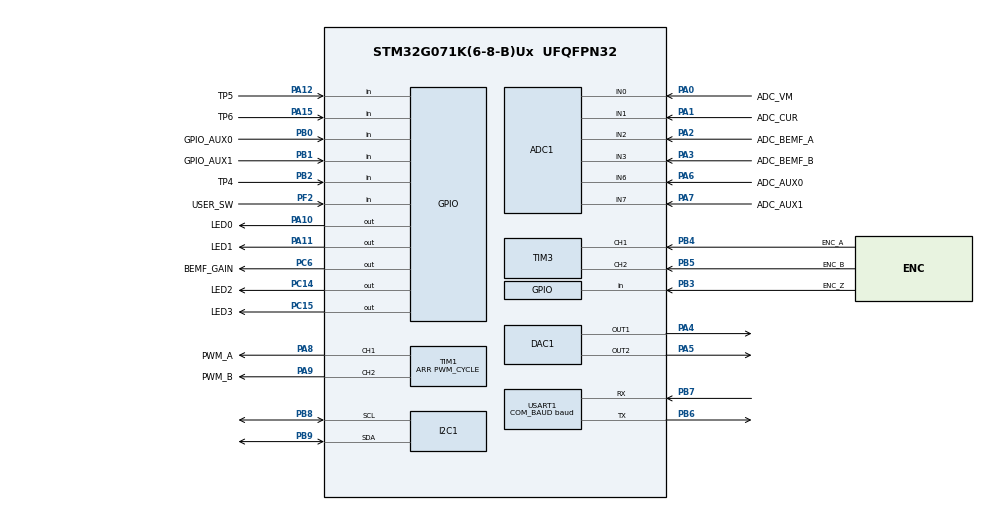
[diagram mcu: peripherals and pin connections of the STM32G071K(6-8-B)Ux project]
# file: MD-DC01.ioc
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ADC1.Channel-0\#ChannelRegularConversion=ADC_CHANNEL_0
ADC1.Channel-1\#ChannelRegularConversion=ADC_CHANNEL_1
ADC1.Channel-2\#ChannelRegularConversion=ADC_CHANNEL_2
ADC1.Channel-3\#ChannelRegularConversion=ADC_CHANNEL_3
ADC1.Channel-4\#ChannelRegularConversion=ADC_CHANNEL_VREFINT
ADC1.Channel-5\#ChannelRegularConversion=ADC_CHANNEL_6
ADC1.Channel-6\#ChannelRegularConversion=ADC_CHANNEL_7
ADC1.ContinuousConvMode=ENABLE
ADC1.DMAContinuousRequests=ENABLE
ADC1.DataAlign=ADC_DATAALIGN_LEFT
ADC1.ExternalTrigConv=ADC_SOFTWARE_START
ADC1.NbrOfConversion=7
ADC1.NbrOfConversionFlag=1
ADC1.Rank-0\#ChannelRegularConversion=1
ADC1.Rank-1\#ChannelRegularConversion=2
ADC1.Rank-2\#ChannelRegularConversion=3
ADC1.Rank-3\#ChannelRegularConversion=4
ADC1.Rank-4\#ChannelRegularConversion=5
ADC1.Rank-5\#ChannelRegularConversion=6
ADC1.Rank-6\#ChannelRegularConversion=7
ADC1.SamplingTime-0\#ChannelRegularConversion=ADC_SAMPLINGTIME_COMMON_1
ADC1.SamplingTime-1\#ChannelRegularConversion=ADC_SAMPLINGTIME_COMMON_1
ADC1.SamplingTime-2\#ChannelRegularConversion=ADC_SAMPLINGTIME_COMMON_1
ADC1.SamplingTime-3\#ChannelRegularConversion=ADC_SAMPLINGTIME_COMMON_1
ADC1.SamplingTime-4\#ChannelRegularConversion=ADC_SAMPLINGTIME_COMMON_2
ADC1.SamplingTime-5\#ChannelRegularConversion=ADC_SAMPLINGTIME_COMMON_2
ADC1.SamplingTime-6\#ChannelRegularConversion=ADC_SAMPLINGTIME_COMMON_2
ADC1.SamplingTimeCommon1=ADC_SAMPLETIME_79CYCLES_5
ADC1.SamplingTimeCommon2=ADC_SAMPLETIME_160CYCLES_5
ADC1.SelectedChannel=ADC_CHANNEL_0|ADC_CHANNEL_1|ADC_CHANNEL_2|ADC_CHANNEL_3|ADC_CHANNEL_6|ADC_CHANNEL_7|ADC_CHANNEL_VREFINT
ADC1.master=1
DAC1.DAC_Channel-DAC_OUT1=DAC_CHANNEL_1
DAC1.DAC_Channel-DAC_OUT2=DAC_CHANNEL_2
Dma.ADC1.0.Direction=DMA_PERIPH_TO_MEMORY
Dma.ADC1.0.EventEnable=DISABLE
Dma.ADC1.0.Instance=DMA1_Channel1
Dma.ADC1.0.MemDataAlignment=DMA_MDATAALIGN_HALFWORD
Dma.ADC1.0.MemInc=DMA_MINC_ENABLE
Dma.ADC1.0.Mode=DMA_CIRCULAR
Dma.ADC1.0.PeriphDataAlignment=DMA_PDATAALIGN_HALFWORD
Dma.ADC1.0.PeriphInc=DMA_PINC_DISABLE
Dma.ADC1.0.Polarity=HAL_DMAMUX_REQ_GEN_RISING
Dma.ADC1.0.Priority=DMA_PRIORITY_VERY_HIGH
Dma.ADC1.0.RequestNumber=1
Dma.ADC1.0.SignalID=NONE
Dma.ADC1.0.SyncEnable=DISABLE
Dma.ADC1.0.SyncPolarity=HAL_DMAMUX_SYNC_NO_EVENT
Dma.ADC1.0.SyncRequestNumber=1
Dma.ADC1.0.SyncSignalID=NONE
Dma.Request0=ADC1
Dma.Request1=USART1_TX
Dma.USART1_TX.1.Direction=DMA_MEMORY_TO_PERIPH
Dma.USART1_TX.1.EventEnable=DISABLE
Dma.USART1_TX.1.Instance=DMA1_Channel2
Dma.USART1_TX.1.MemDataAlignment=DMA_MDATAALIGN_BYTE
Dma.USART1_TX.1.MemInc=DMA_MINC_ENABLE
Dma.USART1_TX.1.Mode=DMA_NORMAL
Dma.USART1_TX.1.PeriphDataAlignment=DMA_PDATAALIGN_BYTE
Dma.USART1_TX.1.PeriphInc=DMA_PINC_DISABLE
Dma.USART1_TX.1.Polarity=HAL_DMAMUX_REQ_GEN_RISING
Dma.USART1_TX.1.Priority=DMA_PRIORITY_HIGH
Dma.USART1_TX.1.RequestNumber=1
Dma.USART1_TX.1.SignalID=NONE
Dma.USART1_TX.1.SyncEnable=DISABLE
Dma.USART1_TX.1.SyncPolarity=HAL_DMAMUX_SYNC_NO_EVENT
Dma.USART1_TX.1.SyncRequestNumber=1
Dma.USART1_TX.1.SyncSignalID=NONE
I2C1.Timing=0x10707DBC
IWDG.Prescaler=IWDG_PRESCALER_32
IWDG.Reload=200
Mcu.Family=STM32G0
Mcu.Name=STM32G071K(6-8-B)Ux
Mcu.Package=UFQFPN32
Mcu.UserConstants=PWM_CYCLE,((PWM_CLOCK / PWM_HZ) - 1);COM_BAUD,(115200);PWM_HZ,(100*1000);PWM_CLOCK,(64*1000*1000)
NVIC.DMA1_Channel1_IRQn=true\:1\:0\:true\:false\:true\:false\:true\:true
NVIC.DMA1_Channel2_3_IRQn=true\:2\:0\:true\:false\:true\:false\:true\:true
NVIC.TIM1_BRK_UP_TRG_COM_IRQn=true\:0\:0\:true\:false\:true\:true\:true\:true
NVIC.USART1_IRQn=true\:0\:0\:false\:false\:true\:true\:true\:true
PA0.GPIO_Label=ADC_VM
PA0.Mode=IN0
PA0.Signal=ADC1_IN0
PA1.GPIO_Label=ADC_CUR
PA1.Mode=IN1
PA1.Signal=ADC1_IN1
PA10.GPIO_Label=LED0
PA10.Signal=GPIO_Output
PA11\ [PA9].GPIO_Label=LED1
PA11\ [PA9].Signal=GPIO_Output
PA12\ [PA10].GPIO_Label=TP5
PA12\ [PA10].Signal=GPIO_Input
PA13.Mode=Serial_Wire
PA13.Signal=SYS_SWDIO
PA14-BOOT0.Mode=Serial_Wire
PA14-BOOT0.Signal=SYS_SWCLK
PA15.GPIO_Label=TP6
PA15.Signal=GPIO_Input
PA2.GPIO_Label=ADC_BEMF_A
PA2.Mode=IN2
PA2.Signal=ADC1_IN2
PA3.GPIO_Label=ADC_BEMF_B
PA3.Mode=IN3
PA3.Signal=ADC1_IN3
PA4.Signal=COMP_DAC11_group
PA5.Signal=COMP_DAC12_group
PA6.GPIO_Label=ADC_AUX0
PA6.Mode=IN6
PA6.Signal=ADC1_IN6
PA7.GPIO_Label=ADC_AUX1
PA7.Mode=IN7
PA7.Signal=ADC1_IN7
PA8.GPIO_Label=PWM_A
PA8.Signal=S_TIM1_CH1
PA9.GPIO_Label=PWM_B
PA9.Signal=S_TIM1_CH2
PB0.GPIO_Label=GPIO_AUX0
PB0.Signal=GPIO_Input
PB1.GPIO_Label=GPIO_AUX1
PB1.Signal=GPIO_Input
PB2.GPIO_Label=TP4
PB2.Signal=GPIO_Input
PB3.GPIO_Label=ENC_Z
PB3.Signal=GPIO_Input
PB4.GPIO_Label=ENC_A
PB4.Signal=S_TIM3_CH1
PB5.GPIO_Label=ENC_B
PB5.Signal=S_TIM3_CH2
PB6.Mode=Asynchronous
PB6.Signal=USART1_TX
PB7.Mode=Asynchronous
PB7.Signal=USART1_RX
PB8.Mode=I2C
PB8.Signal=I2C1_SCL
PB9.Mode=I2C
PB9.Signal=I2C1_SDA
PC14-OSC32_IN\ (PC14).GPIO_Label=LED2
PC14-OSC32_IN\ (PC14).Signal=GPIO_Output
PC15-OSC32_OUT\ (PC15).GPIO_Label=LED3
PC15-OSC32_OUT\ (PC15).Signal=GPIO_Output
PC6.GPIO_Label=BEMF_GAIN
PC6.Signal=GPIO_Output
PF2\ -\ NRST.GPIO_Label=USER_SW
PF2\ -\ NRST.GPIO_PuPd=GPIO_PULLUP
PF2\ -\ NRST.Signal=GPIO_Input
ProjectManager.HeapSize=0x200
ProjectManager.StackSize=0x400
ProjectManager.TargetToolchain=CMake
RCC.ADCFreq_Value=64000000
RCC.AHBFreq_Value=64000000
RCC.CortexFreq_Value=64000000
RCC.EXTERNAL_CLOCK_VALUE=48000
RCC.HCLKFreq_Value=64000000
RCC.HSE_VALUE=8000000
RCC.HSI_VALUE=16000000
RCC.LSE_VALUE=32768
RCC.SYSCLKFreq_VALUE=64000000
RCC.SYSCLKSource=RCC_SYSCLKSOURCE_PLLCLK
RCC.VCOOutputFreq_Value=128000000
SH.COMP_DAC11_group.0=DAC1_OUT1,DAC_OUT1
SH.COMP_DAC12_group.0=DAC1_OUT2,DAC_OUT2
SH.S_TIM1_CH1.0=TIM1_CH1,PWM Generation1 CH1
SH.S_TIM1_CH2.0=TIM1_CH2,PWM Generation2 CH2
SH.S_TIM3_CH1.0=TIM3_CH1,Encoder_Interface
SH.S_TIM3_CH2.0=TIM3_CH2,Encoder_Interface
TIM1.AutoReloadPreload=TIM_AUTORELOAD_PRELOAD_ENABLE
TIM1.Channel-PWM\ Generation1\ CH1=TIM_CHANNEL_1
TIM1.Channel-PWM\ Generation2\ CH2=TIM_CHANNEL_2
TIM1.OCIdleState_1=TIM_OCIDLESTATE_SET
TIM1.OCIdleState_2=TIM_OCIDLESTATE_SET
TIM1.OCPolarity_1=TIM_OCPOLARITY_LOW
TIM1.OCPolarity_2=TIM_OCPOLARITY_LOW
TIM1.Period=PWM_CYCLE
TIM1.TIM_MasterOutputTrigger2=TIM_TRGO2_RESET
TIM3.AutoReloadPreload=TIM_AUTORELOAD_PRELOAD_ENABLE
TIM3.EncoderMode=TIM_ENCODERMODE_TI12
USART1.BaudRate=COM_BAUD
USART1.OverSampling=UART_OVERSAMPLING_8
USART1.OverrunDisableParam=ADVFEATURE_OVERRUN_DISABLE
USART1.VirtualMode-Asynchronous=VM_ASYNC
VP_ADC1_Vref_Input.Mode=IN-Vrefint
VP_IWDG_VS_IWDG.Mode=IWDG_Activate
VP_SYS_VS_DBSignals.Mode=DisableDeadBatterySignals
VP_TIM1_VS_ClockSourceINT.Mode=Internal
board=custom

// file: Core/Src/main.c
/* USER CODE BEGIN Header */
/**
  ******************************************************************************
  * @file           : main.c
  * @brief          : Main program body
  ******************************************************************************
  * @attention
  *
  * Copyright (c) 2023 STMicroelectronics.
  * All rights reserved.
  *
  * This software is licensed under terms that can be found in the LICENSE file
  * in the root directory of this software component.
  * If no LICENSE file comes with this software, it is provided AS-IS.
  *
  ******************************************************************************
  */
/* USER CODE END Header */
#include "main.h"

/* USER CODE BEGIN Includes */
#include "xprintf.h"

#include "led.h"
#include "motor_profiles.h"
#include "usart.h"
#include <stdint.h>
/* USER CODE END Includes */

/* USER CODE BEGIN PTD */
typedef enum
{
  ST_INIT,
  ST_AD_LOW_ZERO,
  ST_AD_HIGH_ZERO,
  ST_RUN
} STATUS;

typedef enum
{
  ADC_GAIN_LOW,
  ADC_GAIN_HIGH
} ADC_GAIN;

typedef enum
{
  ADC1_CH_VM,
  ADC1_CH_CUR,
  ADC1_CH_BEMF_A,
  ADC1_CH_BEMF_B,
  ADC1_CH_VREF,
  ADC1_CH_AUX0,
  ADC1_CH_AUX1,
  ADC1_CH_NUM
} ADC1_CH;

typedef enum
{
  CTRL_VOLT,
  CTRL_VEL,
  CTRL_POS
} CTRL_MODE;

/* USER CODE END PTD */

/* USER CODE BEGIN PD */
#define ADC1_SUM_NUM (1)
#define ADC1_BUF_LEN (ADC1_CH_NUM * ADC1_SUM_NUM)

/* USER CODE END PD */

/* USER CODE BEGIN PV */

// Main process
const static uint32_t ReportIntervalMs = 10;
const static uint32_t AdcZeroDurationMs = 500;
uint32_t ms_ = 0;
static uint32_t report_ms_prev_ = 0;
static uint32_t state_ms_prev_ = 0;
static STATUS state_ = ST_INIT;
static CTRL_MODE mode_ = CTRL_VOLT;

// ADC
const static int32_t AdcExtQ = 4;
const static int32_t AdcLpfQ = 4;
const static int32_t AdcLpfFo = 1;
const static int32_t AdcLpfDnm = 1 << AdcLpfQ;
const static int32_t AdcLpf1_Fo = AdcLpfDnm - AdcLpfFo;
const static int32_t AdcVrefMv = 1212;
const static int32_t BemfDeadBandRaw = 32;

static uint16_t adc1_results_[ADC1_BUF_LEN];
static volatile ADC_GAIN bemf_gain_ = ADC_GAIN_LOW;
static int32_t cur_raw_zero_ = 0;
static int32_t cur_sum_raw_ = 0;
static int32_t cur_sum_num_ = 0;
static bool do_cur_meas_ = false;
static int32_t cur_ma_ = 0;
static int32_t bemf_a_raw_ = 0;
static int32_t bemf_a_high_zero_ = 0;
static int32_t bemf_a_low_zero_ = 0;
static int32_t bemf_b_raw_ = 0;
static int32_t bemf_b_high_zero_ = 0;
static int32_t bemf_b_low_zero_ = 0;
static int32_t bemf_mv_ = 0;
static int32_t vref_raw_ = 0;
static int32_t v_dclink_raw_ = 0;
static int32_t v_dclink_mv_ = 0;
static int32_t adc_aux0_ = 0;
static int32_t adc_aux1_ = 0;
static bool zero_update_ = false;
static bool do_bemf_meas_ = false;

// PWM
const static int32_t BemfMeasureCycle = 250;
const static int32_t BemfMeasureDelay = 10;
const static int32_t BemfMeasureDuration = 50;
const static int32_t BemfDriveDuration = BemfMeasureCycle - BemfMeasureDuration;

static bool enable_output_ = false;
static int32_t bemf_meas_cnt_ = 0;
static int32_t bemf_meas_outoff_ = BemfMeasureCycle - BemfMeasureDuration - 1;
static int32_t bemf_meas_start_ = BemfMeasureCycle - BemfMeasureDuration + BemfMeasureDelay - 1;
static int32_t bemf_meas_end_ = BemfMeasureCycle - 1;
static int32_t oc_ = 0;

// Control
static int32_t target_mv_ = 0;
static int32_t vout_lim_ = 0;
static int32_t v_i_sum_ = 0;
static int32_t vout_mv_ = 0;
const static int32_t ZeroHoldDeadBandMv = 5;
const static int32_t ZeroHoldEnterCycles = 20; // 50 ms at the 2.5 ms control period
static int32_t zero_target_cycles_ = 0;
static bool zero_hold_prev_ = false;

const static int32_t CtrlGainQ = 4;
const static int32_t GainKneeMv = 300;
const static int32_t GainExtra = 10;         // on top of the schedule at very low speed
const static int32_t GainExtraKneeMv = 20;
const static int32_t IntegralGainMinQ4 = 32; // integral stays usable above the knee. Higher feels springy
const static int32_t IntegralClampMv = 200;  // largest error integrated per cycle
const static int32_t BemfSpikeMv = 50;
const static int32_t TargetRampMv = 10;      // per control cycle
static int32_t gain_prev_q4_ = 0;
static int32_t bemf_sum_mv_ = 0;
static int32_t bemf_sum_num_ = 0;
static int32_t target_ref_mv_ = 0;
static int32_t bemf_prev_mv_ = 0;
static bool bemf_held_ = false;
static int32_t gain_multiplier_q4_ = 0;
static int32_t gain_scheduled_q4_ = 0;

static const CtrlConfs * p_mt_conf_ = &MtConfDefault;

// Watchdog
static volatile uint32_t pwm_cb_cnt_ = 0;

// PC command
const static uint32_t PcTargetTimeoutMs = 500;
static bool pc_mode_ = false;
static int32_t pc_target_mv_ = 0;
static uint32_t pc_target_ms_ = 0;

/* USER CODE END PV */

void SystemClock_Config(void);
static void MX_GPIO_Init(void);
static void MX_DMA_Init(void);
static void MX_ADC1_Init(void);
static void MX_DAC1_Init(void);
static void MX_I2C1_Init(void);
static void MX_TIM1_Init(void);
static void MX_TIM3_Init(void);
static void MX_USART1_UART_Init(void);
static void MX_IWDG_Init(void);
/* USER CODE BEGIN PFP */
int absi(const int i);
void adc_init();
void adc_set_gain(const ADC_GAIN g);
void adc_enable_zero_update();
void adc_disable_zero_update();
void adc_enable_bemf_update();
void adc_disable_bemf_update();
void adc_update_bemf();
void adc_latch_cur(const int32_t pwm_oc);
int adc_get_vm();
int adc_get_bemf();
void pwm_init();
void pwm_set_duty(const int32_t rate_q15);
void pwm_enable();
void pwm_disable();
void update_params();
/* USER CODE END PFP */

/* USER CODE BEGIN 0 */
int absi(const int i)
{
  return i < 0 ? -i : i;
}

void adc_init()
{
  LL_DMA_DisableChannel(DMA1, LL_DMA_CHANNEL_1);
  LL_ADC_REG_StopConversion(ADC1);
  LL_ADC_REG_SetDMATransfer(ADC1, LL_ADC_REG_DMA_TRANSFER_NONE);
  LL_ADC_StartCalibration(ADC1);
  while(LL_ADC_IsCalibrationOnGoing(ADC1));
  LL_mDelay(1);
  LL_ADC_REG_ReadConversionData12(ADC1);

  LL_DMA_SetDataLength(DMA1, LL_DMA_CHANNEL_1, ADC1_BUF_LEN);
  LL_DMA_SetPeriphAddress(DMA1, LL_DMA_CHANNEL_1,
                          LL_ADC_DMA_GetRegAddr(ADC1, LL_ADC_DMA_REG_REGULAR_DATA));
  LL_DMA_SetMemoryAddress(DMA1, LL_DMA_CHANNEL_1,
                          (uint32_t)adc1_results_);
  LL_DMA_EnableIT_TC(DMA1, LL_DMA_CHANNEL_1);
  LL_DMA_EnableChannel(DMA1, LL_DMA_CHANNEL_1);

  LL_ADC_REG_SetDMATransfer(ADC1, LL_ADC_REG_DMA_TRANSFER_UNLIMITED);
  LL_ADC_Enable(ADC1);
  LL_ADC_REG_StartConversion(ADC1);
}

void adc_cb()
{
  vref_raw_ = (((int32_t)adc1_results_[ADC1_CH_VREF] << AdcExtQ) * AdcLpfFo
                + vref_raw_ * AdcLpf1_Fo) >> AdcLpfQ;
  v_dclink_raw_ = (((int32_t)adc1_results_[ADC1_CH_VM] << AdcExtQ) * AdcLpfFo
                + v_dclink_raw_ * AdcLpf1_Fo) >> AdcLpfQ;
  const int32_t cur_ext = (int32_t)adc1_results_[ADC1_CH_CUR] << AdcExtQ;
  if (do_cur_meas_)
  {
    cur_sum_raw_ += cur_ext - cur_raw_zero_;
    cur_sum_num_++;
  }
  adc_aux0_ = ((int32_t)adc1_results_[ADC1_CH_AUX0] * AdcLpfFo
                + adc_aux0_ * AdcLpf1_Fo) >> AdcLpfQ;
  adc_aux1_ = ((int32_t)adc1_results_[ADC1_CH_AUX1] * AdcLpfFo
                + adc_aux1_ * AdcLpf1_Fo) >> AdcLpfQ;
  if (zero_update_)
  {
    cur_raw_zero_ = (cur_ext * AdcLpfFo
                    + cur_raw_zero_ * AdcLpf1_Fo) >> AdcLpfQ;
    if (bemf_gain_ == ADC_GAIN_HIGH)
    {
      bemf_a_high_zero_ = (((int32_t)adc1_results_[ADC1_CH_BEMF_A] << AdcExtQ) * AdcLpfFo
                          + bemf_a_high_zero_ * AdcLpf1_Fo) >> AdcLpfQ;
      bemf_b_high_zero_ = (((int32_t)adc1_results_[ADC1_CH_BEMF_B] << AdcExtQ) * AdcLpfFo
                          + bemf_b_high_zero_ * AdcLpf1_Fo) >> AdcLpfQ;
    }
    else
    {
      bemf_a_low_zero_ = (((int32_t)adc1_results_[ADC1_CH_BEMF_A] << AdcExtQ) * AdcLpfFo
                          + bemf_a_low_zero_ * AdcLpf1_Fo) >> AdcLpfQ;
      bemf_b_low_zero_ = (((int32_t)adc1_results_[ADC1_CH_BEMF_B] << AdcExtQ) * AdcLpfFo
                          + bemf_b_low_zero_ * AdcLpf1_Fo) >> AdcLpfQ;
    }
  }
  if (do_bemf_meas_)
    adc_update_bemf();
}

void adc_set_gain(const ADC_GAIN g)
{
  bemf_gain_ = g;
  if (bemf_gain_ == ADC_GAIN_HIGH)
    LL_GPIO_SetOutputPin(BEMF_GAIN_GPIO_Port, BEMF_GAIN_Pin);
  else
    LL_GPIO_ResetOutputPin(BEMF_GAIN_GPIO_Port, BEMF_GAIN_Pin);
}

void adc_enable_zero_update()
{
  zero_update_ = true;
}

void adc_disable_zero_update()
{
  zero_update_ = false;
}

void adc_enable_bemf_update()
{
  do_bemf_meas_ = true;
}

void adc_disable_bemf_update()
{
  do_bemf_meas_ = false;
}

void adc_update_bemf()
{
  int bemf_raw;
  int bemf_mv_raw;
  if (bemf_gain_ == ADC_GAIN_HIGH)
  {
    bemf_a_raw_ = ((int32_t)adc1_results_[ADC1_CH_BEMF_A] << AdcExtQ) - bemf_a_high_zero_;
    bemf_b_raw_ = ((int32_t)adc1_results_[ADC1_CH_BEMF_B] << AdcExtQ) - bemf_b_high_zero_;
    bemf_raw = bemf_a_raw_ > bemf_b_raw_ ? bemf_a_raw_ : -bemf_b_raw_;
    if (bemf_raw > BemfDeadBandRaw) bemf_raw -= BemfDeadBandRaw;
    else if (bemf_raw < -BemfDeadBandRaw) bemf_raw += BemfDeadBandRaw;
    else bemf_raw = 0;
    bemf_mv_raw = (int64_t)bemf_raw * AdcVrefMv * 1249 * 143 / ((int64_t)vref_raw_ * 249 * 1143);
  }
  else
  {
    bemf_a_raw_ = ((int32_t)adc1_results_[ADC1_CH_BEMF_A] << AdcExtQ) - bemf_a_low_zero_;
    bemf_b_raw_ = ((int32_t)adc1_results_[ADC1_CH_BEMF_B] << AdcExtQ) - bemf_b_low_zero_;
    bemf_raw = bemf_a_raw_ > bemf_b_raw_ ? bemf_a_raw_ : -bemf_b_raw_;
    if (bemf_raw > BemfDeadBandRaw) bemf_raw -= BemfDeadBandRaw;
    else if (bemf_raw < -BemfDeadBandRaw) bemf_raw += BemfDeadBandRaw;
    else bemf_raw = 0;
    bemf_mv_raw = (int64_t)bemf_raw * AdcVrefMv * 1249 / (vref_raw_ * 249);
  }
  bemf_sum_mv_ += bemf_mv_raw;
  bemf_sum_num_++;
}

// The shunt only carries current during the on-time, so the drive period mean is divided by the duty.
void adc_latch_cur(const int32_t pwm_oc)
{
  do_cur_meas_ = false;
  int32_t ma = 0;
  if (absi(pwm_oc) >= 6)
  {
    const int32_t mean_raw = cur_sum_raw_ / cur_sum_num_;
    if (mean_raw > 0)
    {
      ma = (int64_t)mean_raw * AdcVrefMv * 50 * PWM_CYCLE / ((int64_t)vref_raw_ * 51 * absi(pwm_oc));
    }
  }
  cur_ma_ = pwm_oc < 0 ? -ma : ma;
}

int adc_get_vm()
{
  return (int64_t)v_dclink_raw_ * AdcVrefMv * 11 / vref_raw_;
}

int adc_get_bemf()
{
  return bemf_mv_;
}

void set_oc()
{
  if (oc_ > 0)
  {
    LL_TIM_OC_SetCompareCH1(PwmTim, 0);
    LL_TIM_OC_SetCompareCH2(PwmTim, oc_);
  }
  else if (oc_ < 0)
  {
    LL_TIM_OC_SetCompareCH1(PwmTim, -oc_);
    LL_TIM_OC_SetCompareCH2(PwmTim, 0);
  }
  else
  {
    LL_TIM_OC_SetCompareCH1(PwmTim, 0);
    LL_TIM_OC_SetCompareCH2(PwmTim, 0);
  }
}

void output_open()
{
  LL_TIM_OC_SetCompareCH1(PwmTim, PWM_CYCLE);
  LL_TIM_OC_SetCompareCH2(PwmTim, PWM_CYCLE);
}

void pwm_init()
{
  pwm_set_duty(0);
  pwm_disable();
  LL_TIM_CC_EnableChannel(PwmTim, LL_TIM_CHANNEL_CH1 | LL_TIM_CHANNEL_CH2);
  LL_TIM_EnableAllOutputs(PwmTim);
  LL_TIM_EnableIT_UPDATE(PwmTim);
  LL_TIM_EnableCounter(PwmTim);
}

/*
rate_q15 : -32768 to 32767
*/
void pwm_set_duty(const int32_t rate_q15)
{
  oc_ = rate_q15 * PWM_CYCLE >> 15;
  if (oc_ >= PWM_CYCLE) oc_ = PWM_CYCLE - 1;
  else if (oc_ <= -PWM_CYCLE) oc_ = -(PWM_CYCLE - 1);
}

void pwm_set_mv(const int32_t mv)
{
  int32_t duty = 0;
  duty = (int64_t)mv * (1<<15) * BemfMeasureCycle / (v_dclink_mv_ * BemfDriveDuration);
  pwm_set_duty(duty);
}

void pwm_enable()
{
  enable_output_ = true;
}

void pwm_disable()
{
  enable_output_ = false;
  output_open();
}

void update_params()
{
  bemf_mv_ = adc_get_bemf();
  v_dclink_mv_ = adc_get_vm();
  // pwm_cb reads vout_lim_, so it must never hold the value before clamping.
  int32_t vout_lim = v_dclink_mv_ * BemfDriveDuration / BemfMeasureCycle;
  if (vout_lim > p_mt_conf_->max_mv) vout_lim = p_mt_conf_->max_mv;
  vout_lim_ = vout_lim;
}

void pwm_cb()
{
  pwm_cb_cnt_++;
  bemf_meas_cnt_++;
  if (bemf_meas_cnt_ == bemf_meas_end_)
  {
    bemf_meas_cnt_ = 0;
    adc_disable_bemf_update();

    if (mode_ != CTRL_VOLT)
    {
      led_on(0);
      // Averaged within this window only, so it adds no delay across control cycles.
      bemf_mv_ = bemf_sum_mv_ / bemf_sum_num_;
      bemf_sum_mv_ = 0;
      bemf_sum_num_ = 0;

      // The rotor cannot jump in one cycle, so a single far off value is a measurement spike.
      // Only needed below the knee: the high gain there would turn it into a large output step.
      if (absi(target_ref_mv_) < GainKneeMv
          && absi(bemf_mv_ - bemf_prev_mv_) > BemfSpikeMv + absi(target_ref_mv_) && !bemf_held_)
      {
        bemf_mv_ = bemf_prev_mv_;
        bemf_held_ = true;
      }
      else
      {
        bemf_held_ = false;
      }
      bemf_prev_mv_ = bemf_mv_;

      if (target_mv_ > target_ref_mv_ + TargetRampMv) target_ref_mv_ += TargetRampMv;
      else if (target_mv_ < target_ref_mv_ - TargetRampMv) target_ref_mv_ -= TargetRampMv;
      else target_ref_mv_ = target_mv_;

      // A target that only touches 0 at very low speed must not reset the integrator.
      if (target_ref_mv_ != 0) zero_target_cycles_ = 0;
      else if (zero_target_cycles_ < ZeroHoldEnterCycles) zero_target_cycles_++;
      const bool zero_hold = (zero_target_cycles_ >= ZeroHoldEnterCycles);
      int32_t err = target_ref_mv_ - bemf_mv_;
      int32_t vout;
      int32_t vout_tmp;

      // The integral built while running would keep driving a slow rotation that BEMF cannot detect.
      if (zero_hold && !zero_hold_prev_) v_i_sum_ = 0;
      zero_hold_prev_ = zero_hold;

      // Inside the band err is 0, so the integrator keeps the torque holding against cogging.
      if (zero_hold)
      {
        if (err > ZeroHoldDeadBandMv) err -= ZeroHoldDeadBandMv;
        else if (err < -ZeroHoldDeadBandMv) err += ZeroHoldDeadBandMv;
        else err = 0;
      }

      // The gain also scales the integral, so rescale it to keep its output across gain changes.
      const int32_t gain_i_q4 = gain_scheduled_q4_ > IntegralGainMinQ4 ? gain_scheduled_q4_ : IntegralGainMinQ4;
      if (gain_prev_q4_ != 0 && gain_i_q4 != gain_prev_q4_)
      {
        v_i_sum_ = (int64_t)v_i_sum_ * gain_prev_q4_ / gain_i_q4;
      }
      gain_prev_q4_ = gain_i_q4;

      // A limit rather than a stop, so a large error from a heavy load still reaches the integral.
      int32_t i_add = err;
      if (i_add > IntegralClampMv) i_add = IntegralClampMv;
      else if (i_add < -IntegralClampMv) i_add = -IntegralClampMv;
      v_i_sum_ += i_add;

      // feedforward
      vout = (target_ref_mv_ * (p_mt_conf_->v_ff_kp_q8)) >> CtrlQ;

      // feedback
      const int32_t fb_p = ((int64_t)err * (p_mt_conf_->v_kp_q8)) >> CtrlQ;
      const int32_t fb_i = ((int64_t)v_i_sum_ * (p_mt_conf_->v_ti_q8)) >> CtrlQ;

      vout += (fb_p * gain_scheduled_q4_) >> CtrlGainQ;
      vout += (fb_i * gain_i_q4) >> CtrlGainQ;

      // compensate brush voltage drop
      // Skipped at zero target: the step at vout = 0 would flip the output by +-brush_co_mv.
      if (!zero_hold)
      {
        if (vout > 0) vout += p_mt_conf_->brush_co_mv;
        else if (vout < 0) vout -= p_mt_conf_->brush_co_mv;
      }

      vout_tmp = vout;

      // limit output
      if (vout > vout_lim_) vout = vout_lim_;
      else if (vout < -vout_lim_) vout = -vout_lim_;

      // cut output while over the current limit
      if (absi(cur_ma_) > p_mt_conf_->max_cur) vout = 0;

      // unti windup
      if ((vout < vout_tmp && err > 0)
          || (vout > vout_tmp && err < 0))
      {
        v_i_sum_ -= i_add;
      }

      vout_mv_ = vout;
      pwm_set_mv(vout);
      led_off(0);
    }
    if (enable_output_)
      set_oc();
    cur_sum_raw_ = 0;
    cur_sum_num_ = 0;
    do_cur_meas_ = true;
  }
  else if (bemf_meas_cnt_ == bemf_meas_outoff_)
  {
    output_open();
    adc_latch_cur(oc_);
  }
  else if (bemf_meas_cnt_ == bemf_meas_start_)
  {
    adc_enable_bemf_update();
  }
}

static bool parse_mv(const char* s, int32_t* mv)
{
  const bool neg = (*s == '-');
  if (neg) ++s;
  if (*s == '\0') return false;
  int32_t val = 0;
  for (; *s != '\0'; ++s)
  {
    if (*s < '0' || *s > '9' || val > 100000) return false;
    val = val * 10 + (*s - '0');
  }
  *mv = neg ? -val : val;
  return true;
}

/*
T<mv> : switch to PC mode and set the target. Must be repeated within PcTargetTimeoutMs.
K     : switch back to the knob.
*/
static void pc_command_poll()
{
  char line[16];
  if (usart_readline(line, sizeof(line)) == 0) return;

  int32_t mv;
  if (line[0] == 'T' && parse_mv(&line[1], &mv))
  {
    if (mv > p_mt_conf_->max_mv) mv = p_mt_conf_->max_mv;
    else if (mv < -p_mt_conf_->max_mv) mv = -p_mt_conf_->max_mv;
    pc_target_mv_ = mv;
    pc_target_ms_ = ms_;
    pc_mode_ = true;
  }
  else if (line[0] == 'K' && line[1] == '\0')
  {
    pc_mode_ = false;
  }
}

/*
Can not use with v1.0 PCB.
*/
int sw_is_pressed()
{
  return LL_GPIO_IsInputPinSet(USER_SW_GPIO_Port, USER_SW_Pin);
}
/* USER CODE END 0 */

int main(void)
{

  /* USER CODE BEGIN 1 */
  char report_buf[256];
  /* USER CODE END 1 */

  /* MCU Configuration--------------------------------------------------------*/

  /* Reset of all peripherals, Initializes the Flash interface and the Systick. */
  LL_APB2_GRP1_EnableClock(LL_APB2_GRP1_PERIPH_SYSCFG);
  LL_APB1_GRP1_EnableClock(LL_APB1_GRP1_PERIPH_PWR);

  /* SysTick_IRQn interrupt configuration */
  NVIC_SetPriority(SysTick_IRQn, 3);

  /** Disable the internal Pull-Up in Dead Battery pins of UCPD peripheral
  */
  LL_SYSCFG_DisableDBATT(LL_SYSCFG_UCPD1_STROBE);

  /* Configure the system clock */
  SystemClock_Config();

  /* USER CODE BEGIN SysInit */
  LL_SYSTICK_EnableIT();
  /* USER CODE END SysInit */

  /* Initialize all configured peripherals */
  MX_GPIO_Init();
  MX_DMA_Init();
  MX_ADC1_Init();
  MX_DAC1_Init();
  MX_I2C1_Init();
  MX_TIM1_Init();
  MX_TIM3_Init();
  MX_USART1_UART_Init();
  MX_IWDG_Init();
  /* USER CODE BEGIN 2 */
  pwm_init();
  adc_init();
  usart_init();
  /* USER CODE END 2 */

  /* Infinite loop */
  /* USER CODE BEGIN WHILE */
  adc_set_gain(ADC_GAIN_LOW);
  gain_multiplier_q4_ = (p_mt_conf_->v_gain_schedule_multiplier) << CtrlGainQ;
  gain_scheduled_q4_ = gain_multiplier_q4_;

  uint32_t pwm_cb_cnt_prev = pwm_cb_cnt_;
  while (1)
  {
    // Refresh only while both the main loop and the control interrupt are running.
    if (pwm_cb_cnt_ != pwm_cb_cnt_prev)
    {
      pwm_cb_cnt_prev = pwm_cb_cnt_;
      LL_IWDG_ReloadCounter(IWDG);
    }
    if (sw_is_pressed())
      pwm_disable();
    update_params();
    /* USER CODE END WHILE */

    /* USER CODE BEGIN 3 */
    switch (state_)
    {
    case ST_INIT:
      pwm_disable();
      adc_set_gain(ADC_GAIN_LOW);
      adc_enable_zero_update();
      state_ = ST_AD_LOW_ZERO;
      state_ms_prev_ = ms_;
      break;

    case ST_AD_LOW_ZERO:
      if (ms_ - state_ms_prev_ >= AdcZeroDurationMs)
      {
        adc_set_gain(ADC_GAIN_HIGH);
        state_ = ST_AD_HIGH_ZERO;
        state_ms_prev_ = ms_;
      }
      break;

    case ST_AD_HIGH_ZERO:
      if (ms_ - state_ms_prev_ >= AdcZeroDurationMs)
      {
        adc_set_gain(ADC_GAIN_LOW);
        pwm_enable();
        adc_disable_zero_update();
        state_ = ST_RUN;
        state_ms_prev_ = ms_;
      }
      break;

    case ST_RUN:
    {
      #if 0
      pwm_set_mv((adc_aux0_ - 32768) * 5000 / 32768);
      #endif

      #if 1
      mode_ = CTRL_VEL;
      int target = (adc_aux0_ - 32768) * (p_mt_conf_->max_mv) / 32768;
      const int db = 30;
      if (target > db) target -= db;
      else if (target < -db) target += db;
      else target = 0;

      pc_command_poll();
      if (pc_mode_)
      {
        // Stays in PC mode on timeout: falling back to the knob could start the motor.
        target = (ms_ - pc_target_ms_ < PcTargetTimeoutMs) ? pc_target_mv_ : 0;
      }

      if (target == 0) led_off(3);
      else led_on(3);

      if (absi(target) < 16000/10) adc_set_gain(ADC_GAIN_HIGH);
      else adc_set_gain(ADC_GAIN_LOW);

      target_mv_ = target;

      // High gain only where cogging dominates. Above the knee it just amplifies the BEMF ripple.
      const int32_t gain_scale = GainKneeMv - absi(target_ref_mv_);
      const int32_t gain_extra_scale = GainExtraKneeMv - absi(target_ref_mv_);
      gain_scheduled_q4_ = (1<<CtrlGainQ) + (gain_scale > 0 ? gain_multiplier_q4_ * gain_scale / GainKneeMv : 0)
                           + (gain_extra_scale > 0 ? (GainExtra << CtrlGainQ) * gain_extra_scale / GainExtraKneeMv : 0);
      #endif
    }
      break;
    }

    if (!usart_is_tx_busy() && ms_ - report_ms_prev_ >= ReportIntervalMs)
    {
      report_ms_prev_ += ReportIntervalMs;

      xsprintf(report_buf, "%7d %1d %5d %5d %6d %5d %6d %8d\n",
                ms_, state_, v_dclink_mv_, cur_ma_, bemf_mv_, target_mv_, vout_mv_, v_i_sum_);
      int len = 0;
      while(report_buf[len++] != '\0');
      usart_tx(report_buf, len);
    }
  }
  /* USER CODE END 3 */
}

void SystemClock_Config(void)
{
  LL_FLASH_SetLatency(LL_FLASH_LATENCY_2);
  while(LL_FLASH_GetLatency() != LL_FLASH_LATENCY_2)
  {
  }

  /* HSI configuration and activation */
  LL_RCC_HSI_Enable();
  while(LL_RCC_HSI_IsReady() != 1)
  {
  }

  /* LSI configuration and activation */
  LL_RCC_LSI_Enable();
  while(LL_RCC_LSI_IsReady() != 1)
  {
  }

  /* Main PLL configuration and activation */
  LL_RCC_PLL_ConfigDomain_SYS(LL_RCC_PLLSOURCE_HSI, LL_RCC_PLLM_DIV_1, 8, LL_RCC_PLLR_DIV_2);
  LL_RCC_PLL_Enable();
  LL_RCC_PLL_EnableDomain_SYS();
  while(LL_RCC_PLL_IsReady() != 1)
  {
  }

  /* Set AHB prescaler*/
  LL_RCC_SetAHBPrescaler(LL_RCC_SYSCLK_DIV_1);

  /* Sysclk activation on the main PLL */
  LL_RCC_SetSysClkSource(LL_RCC_SYS_CLKSOURCE_PLL);
  while(LL_RCC_GetSysClkSource() != LL_RCC_SYS_CLKSOURCE_STATUS_PLL)
  {
  }

  /* Set APB1 prescaler*/
  LL_RCC_SetAPB1Prescaler(LL_RCC_APB1_DIV_1);
  LL_Init1msTick(64000000);
  /* Update CMSIS variable (which can be updated also through SystemCoreClockUpdate function) */
  LL_SetSystemCoreClock(64000000);
}

static void MX_ADC1_Init(void)
{

  LL_ADC_InitTypeDef ADC_InitStruct = {0};
  LL_ADC_REG_InitTypeDef ADC_REG_InitStruct = {0};

  LL_GPIO_InitTypeDef GPIO_InitStruct = {0};

  /* Peripheral clock enable */
  LL_APB2_GRP1_EnableClock(LL_APB2_GRP1_PERIPH_ADC);

  LL_IOP_GRP1_EnableClock(LL_IOP_GRP1_PERIPH_GPIOA);
  /**ADC1 GPIO Configuration
  PA0   ------> ADC1_IN0
  PA1   ------> ADC1_IN1
  PA2   ------> ADC1_IN2
  PA3   ------> ADC1_IN3
  PA6   ------> ADC1_IN6
  PA7   ------> ADC1_IN7
  */
  GPIO_InitStruct.Pin = ADC_VM_Pin;
  GPIO_InitStruct.Mode = LL_GPIO_MODE_ANALOG;
  GPIO_InitStruct.Pull = LL_GPIO_PULL_NO;
  LL_GPIO_Init(ADC_VM_GPIO_Port, &GPIO_InitStruct);

  GPIO_InitStruct.Pin = ADC_CUR_Pin;
  GPIO_InitStruct.Mode = LL_GPIO_MODE_ANALOG;
  GPIO_InitStruct.Pull = LL_GPIO_PULL_NO;
  LL_GPIO_Init(ADC_CUR_GPIO_Port, &GPIO_InitStruct);

  GPIO_InitStruct.Pin = ADC_BEMF_A_Pin;
  GPIO_InitStruct.Mode = LL_GPIO_MODE_ANALOG;
  GPIO_InitStruct.Pull = LL_GPIO_PULL_NO;
  LL_GPIO_Init(ADC_BEMF_A_GPIO_Port, &GPIO_InitStruct);

  GPIO_InitStruct.Pin = ADC_BEMF_B_Pin;
  GPIO_InitStruct.Mode = LL_GPIO_MODE_ANALOG;
  GPIO_InitStruct.Pull = LL_GPIO_PULL_NO;
  LL_GPIO_Init(ADC_BEMF_B_GPIO_Port, &GPIO_InitStruct);

  GPIO_InitStruct.Pin = ADC_AUX0_Pin;
  GPIO_InitStruct.Mode = LL_GPIO_MODE_ANALOG;
  GPIO_InitStruct.Pull = LL_GPIO_PULL_NO;
  LL_GPIO_Init(ADC_AUX0_GPIO_Port, &GPIO_InitStruct);

  GPIO_InitStruct.Pin = ADC_AUX1_Pin;
  GPIO_InitStruct.Mode = LL_GPIO_MODE_ANALOG;
  GPIO_InitStruct.Pull = LL_GPIO_PULL_NO;
  LL_GPIO_Init(ADC_AUX1_GPIO_Port, &GPIO_InitStruct);

  /* ADC1 DMA Init */

  /* ADC1 Init */
  LL_DMA_SetPeriphRequest(DMA1, LL_DMA_CHANNEL_1, LL_DMAMUX_REQ_ADC1);

  LL_DMA_SetDataTransferDirection(DMA1, LL_DMA_CHANNEL_1, LL_DMA_DIRECTION_PERIPH_TO_MEMORY);

  LL_DMA_SetChannelPriorityLevel(DMA1, LL_DMA_CHANNEL_1, LL_DMA_PRIORITY_VERYHIGH);

  LL_DMA_SetMode(DMA1, LL_DMA_CHANNEL_1, LL_DMA_MODE_CIRCULAR);

  LL_DMA_SetPeriphIncMode(DMA1, LL_DMA_CHANNEL_1, LL_DMA_PERIPH_NOINCREMENT);

  LL_DMA_SetMemoryIncMode(DMA1, LL_DMA_CHANNEL_1, LL_DMA_MEMORY_INCREMENT);

  LL_DMA_SetPeriphSize(DMA1, LL_DMA_CHANNEL_1, LL_DMA_PDATAALIGN_HALFWORD);

  LL_DMA_SetMemorySize(DMA1, LL_DMA_CHANNEL_1, LL_DMA_MDATAALIGN_HALFWORD);

  /** Configure the global features of the ADC (Clock, Resolution, Data Alignment and number of conversion)
  */

   #define ADC_CHANNEL_CONF_RDY_TIMEOUT_MS ( 1U)
   #if (USE_TIMEOUT == 1)
   uint32_t Timeout ; /* Variable used for Timeout management */
   #endif /* USE_TIMEOUT */

  ADC_InitStruct.Clock = LL_ADC_CLOCK_SYNC_PCLK_DIV2;
  ADC_InitStruct.Resolution = LL_ADC_RESOLUTION_12B;
  ADC_InitStruct.DataAlignment = LL_ADC_DATA_ALIGN_LEFT;
  ADC_InitStruct.LowPowerMode = LL_ADC_LP_MODE_NONE;
  LL_ADC_Init(ADC1, &ADC_InitStruct);
  LL_ADC_REG_SetSequencerConfigurable(ADC1, LL_ADC_REG_SEQ_CONFIGURABLE);

   /* Poll for ADC channel configuration ready */
   #if (USE_TIMEOUT == 1)
   Timeout = ADC_CHANNEL_CONF_RDY_TIMEOUT_MS;
   #endif /* USE_TIMEOUT */
   while (LL_ADC_IsActiveFlag_CCRDY(ADC1) == 0)
     {
   #if (USE_TIMEOUT == 1)
   /* Check Systick counter flag to decrement the time-out value */
   if (LL_SYSTICK_IsActiveCounterFlag())
     {
   if(Timeout-- == 0)
         {
   Error_Handler();
         }
     }
   #endif /* USE_TIMEOUT */
     }
   /* Clear flag ADC channel configuration ready */
   LL_ADC_ClearFlag_CCRDY(ADC1);
  ADC_REG_InitStruct.TriggerSource = LL_ADC_REG_TRIG_SOFTWARE;
  ADC_REG_InitStruct.SequencerLength = LL_ADC_REG_SEQ_SCAN_ENABLE_7RANKS;
  ADC_REG_InitStruct.ContinuousMode = LL_ADC_REG_CONV_CONTINUOUS;
  ADC_REG_InitStruct.DMATransfer = LL_ADC_REG_DMA_TRANSFER_UNLIMITED;
  ADC_REG_InitStruct.Overrun = LL_ADC_REG_OVR_DATA_PRESERVED;
  LL_ADC_REG_Init(ADC1, &ADC_REG_InitStruct);
  LL_ADC_SetOverSamplingScope(ADC1, LL_ADC_OVS_DISABLE);
  LL_ADC_SetTriggerFrequencyMode(ADC1, LL_ADC_CLOCK_FREQ_MODE_HIGH);
  LL_ADC_SetCommonPathInternalCh(__LL_ADC_COMMON_INSTANCE(ADC1), LL_ADC_PATH_INTERNAL_VREFINT);
  LL_ADC_SetSamplingTimeCommonChannels(ADC1, LL_ADC_SAMPLINGTIME_COMMON_1, LL_ADC_SAMPLINGTIME_79CYCLES_5);
  LL_ADC_SetSamplingTimeCommonChannels(ADC1, LL_ADC_SAMPLINGTIME_COMMON_2, LL_ADC_SAMPLINGTIME_160CYCLES_5);
  LL_ADC_DisableIT_EOC(ADC1);
  LL_ADC_DisableIT_EOS(ADC1);

   /* Enable ADC internal voltage regulator */
   LL_ADC_EnableInternalRegulator(ADC1);
   /* Delay for ADC internal voltage regulator stabilization. */
   /* Compute number of CPU cycles to wait for, from delay in us. */
   /* Note: Variable divided by 2 to compensate partially */
   /* CPU processing cycles (depends on compilation optimization). */
   /* Note: If system core clock frequency is below 200kHz, wait time */
   /* is only a few CPU processing cycles. */
   __IO uint32_t wait_loop_index;
   wait_loop_index = ((LL_ADC_DELAY_INTERNAL_REGUL_STAB_US * (SystemCoreClock / (100000 * 2))) / 10);
   while(wait_loop_index != 0)
     {
   wait_loop_index--;
     }

  /** Configure Regular Channel
  */
  LL_ADC_REG_SetSequencerRanks(ADC1, LL_ADC_REG_RANK_1, LL_ADC_CHANNEL_0);
  LL_ADC_SetChannelSamplingTime(ADC1, LL_ADC_CHANNEL_0, LL_ADC_SAMPLINGTIME_COMMON_1);

  /** Configure Regular Channel
  */
  LL_ADC_REG_SetSequencerRanks(ADC1, LL_ADC_REG_RANK_2, LL_ADC_CHANNEL_1);

   /* Poll for ADC channel configuration ready */
   #if (USE_TIMEOUT == 1)
   Timeout = ADC_CHANNEL_CONF_RDY_TIMEOUT_MS;
   #endif /* USE_TIMEOUT */
   while (LL_ADC_IsActiveFlag_CCRDY(ADC1) == 0)
     {
   #if (USE_TIMEOUT == 1)
   /* Check Systick counter flag to decrement the time-out value */
   if (LL_SYSTICK_IsActiveCounterFlag())
     {
   if(Timeout-- == 0)
         {
   Error_Handler();
         }
     }
   #endif /* USE_TIMEOUT */
     }
   /* Clear flag ADC channel configuration ready */
   LL_ADC_ClearFlag_CCRDY(ADC1);
  LL_ADC_SetChannelSamplingTime(ADC1, LL_ADC_CHANNEL_1, LL_ADC_SAMPLINGTIME_COMMON_1);

  /** Configure Regular Channel
  */
  LL_ADC_REG_SetSequencerRanks(ADC1, LL_ADC_REG_RANK_3, LL_ADC_CHANNEL_2);

   /* Poll for ADC channel configuration ready */
   #if (USE_TIMEOUT == 1)
   Timeout = ADC_CHANNEL_CONF_RDY_TIMEOUT_MS;
   #endif /* USE_TIMEOUT */
   while (LL_ADC_IsActiveFlag_CCRDY(ADC1) == 0)
     {
   #if (USE_TIMEOUT == 1)
   /* Check Systick counter flag to decrement the time-out value */
   if (LL_SYSTICK_IsActiveCounterFlag())
     {
   if(Timeout-- == 0)
         {
   Error_Handler();
         }
     }
   #endif /* USE_TIMEOUT */
     }
   /* Clear flag ADC channel configuration ready */
   LL_ADC_ClearFlag_CCRDY(ADC1);
  LL_ADC_SetChannelSamplingTime(ADC1, LL_ADC_CHANNEL_2, LL_ADC_SAMPLINGTIME_COMMON_1);

  /** Configure Regular Channel
  */
  LL_ADC_REG_SetSequencerRanks(ADC1, LL_ADC_REG_RANK_4, LL_ADC_CHANNEL_3);

   /* Poll for ADC channel configuration ready */
   #if (USE_TIMEOUT == 1)
   Timeout = ADC_CHANNEL_CONF_RDY_TIMEOUT_MS;
   #endif /* USE_TIMEOUT */
   while (LL_ADC_IsActiveFlag_CCRDY(ADC1) == 0)
     {
   #if (USE_TIMEOUT == 1)
   /* Check Systick counter flag to decrement the time-out value */
   if (LL_SYSTICK_IsActiveCounterFlag())
     {
   if(Timeout-- == 0)
         {
   Error_Handler();
         }
     }
   #endif /* USE_TIMEOUT */
     }
   /* Clear flag ADC channel configuration ready */
   LL_ADC_ClearFlag_CCRDY(ADC1);
  LL_ADC_SetChannelSamplingTime(ADC1, LL_ADC_CHANNEL_3, LL_ADC_SAMPLINGTIME_COMMON_1);

  /** Configure Regular Channel
  */
  LL_ADC_REG_SetSequencerRanks(ADC1, LL_ADC_REG_RANK_5, LL_ADC_CHANNEL_VREFINT);

   /* Poll for ADC channel configuration ready */
   #if (USE_TIMEOUT == 1)
   Timeout = ADC_CHANNEL_CONF_RDY_TIMEOUT_MS;
   #endif /* USE_TIMEOUT */
   while (LL_ADC_IsActiveFlag_CCRDY(ADC1) == 0)
     {
   #if (USE_TIMEOUT == 1)
   /* Check Systick counter flag to decrement the time-out value */
   if (LL_SYSTICK_IsActiveCounterFlag())
     {
   if(Timeout-- == 0)
         {
   Error_Handler();
         }
     }
   #endif /* USE_TIMEOUT */
     }
   /* Clear flag ADC channel configuration ready */
   LL_ADC_ClearFlag_CCRDY(ADC1);
  LL_ADC_SetChannelSamplingTime(ADC1, LL_ADC_CHANNEL_VREFINT, LL_ADC_SAMPLINGTIME_COMMON_2);

  /** Configure Regular Channel
  */
  LL_ADC_REG_SetSequencerRanks(ADC1, LL_ADC_REG_RANK_6, LL_ADC_CHANNEL_6);

   /* Poll for ADC channel configuration ready */
   #if (USE_TIMEOUT == 1)
   Timeout = ADC_CHANNEL_CONF_RDY_TIMEOUT_MS;
   #endif /* USE_TIMEOUT */
   while (LL_ADC_IsActiveFlag_CCRDY(ADC1) == 0)
     {
   #if (USE_TIMEOUT == 1)
   /* Check Systick counter flag to decrement the time-out value */
   if (LL_SYSTICK_IsActiveCounterFlag())
     {
   if(Timeout-- == 0)
         {
   Error_Handler();
         }
     }
   #endif /* USE_TIMEOUT */
     }
   /* Clear flag ADC channel configuration ready */
   LL_ADC_ClearFlag_CCRDY(ADC1);
  LL_ADC_SetChannelSamplingTime(ADC1, LL_ADC_CHANNEL_6, LL_ADC_SAMPLINGTIME_COMMON_2);

  /** Configure Regular Channel
  */
  LL_ADC_REG_SetSequencerRanks(ADC1, LL_ADC_REG_RANK_7, LL_ADC_CHANNEL_7);

   /* Poll for ADC channel configuration ready */
   #if (USE_TIMEOUT == 1)
   Timeout = ADC_CHANNEL_CONF_RDY_TIMEOUT_MS;
   #endif /* USE_TIMEOUT */
   while (LL_ADC_IsActiveFlag_CCRDY(ADC1) == 0)
     {
   #if (USE_TIMEOUT == 1)
   /* Check Systick counter flag to decrement the time-out value */
   if (LL_SYSTICK_IsActiveCounterFlag())
     {
   if(Timeout-- == 0)
         {
   Error_Handler();
         }
     }
   #endif /* USE_TIMEOUT */
     }
   /* Clear flag ADC channel configuration ready */
   LL_ADC_ClearFlag_CCRDY(ADC1);
  LL_ADC_SetChannelSamplingTime(ADC1, LL_ADC_CHANNEL_7, LL_ADC_SAMPLINGTIME_COMMON_2);

}

static void MX_DAC1_Init(void)
{

  LL_DAC_InitTypeDef DAC_InitStruct = {0};

  LL_GPIO_InitTypeDef GPIO_InitStruct = {0};

  /* Peripheral clock enable */
  LL_APB1_GRP1_EnableClock(LL_APB1_GRP1_PERIPH_DAC1);

  LL_IOP_GRP1_EnableClock(LL_IOP_GRP1_PERIPH_GPIOA);
  /**DAC1 GPIO Configuration
  PA4   ------> DAC1_OUT1
  PA5   ------> DAC1_OUT2
  */
  GPIO_InitStruct.Pin = LL_GPIO_PIN_4;
  GPIO_InitStruct.Mode = LL_GPIO_MODE_ANALOG;
  GPIO_InitStruct.Pull = LL_GPIO_PULL_NO;
  LL_GPIO_Init(GPIOA, &GPIO_InitStruct);

  GPIO_InitStruct.Pin = LL_GPIO_PIN_5;
  GPIO_InitStruct.Mode = LL_GPIO_MODE_ANALOG;
  GPIO_InitStruct.Pull = LL_GPIO_PULL_NO;
  LL_GPIO_Init(GPIOA, &GPIO_InitStruct);

  /** DAC channel OUT1 config
  */
  DAC_InitStruct.TriggerSource = LL_DAC_TRIG_SOFTWARE;
  DAC_InitStruct.WaveAutoGeneration = LL_DAC_WAVE_AUTO_GENERATION_NONE;
  DAC_InitStruct.OutputBuffer = LL_DAC_OUTPUT_BUFFER_ENABLE;
  DAC_InitStruct.OutputConnection = LL_DAC_OUTPUT_CONNECT_GPIO;
  DAC_InitStruct.OutputMode = LL_DAC_OUTPUT_MODE_NORMAL;
  LL_DAC_Init(DAC1, LL_DAC_CHANNEL_1, &DAC_InitStruct);
  LL_DAC_DisableTrigger(DAC1, LL_DAC_CHANNEL_1);

  /** DAC channel OUT2 config
  */
  LL_DAC_Init(DAC1, LL_DAC_CHANNEL_2, &DAC_InitStruct);
  LL_DAC_DisableTrigger(DAC1, LL_DAC_CHANNEL_2);

}

static void MX_I2C1_Init(void)
{

  LL_I2C_InitTypeDef I2C_InitStruct = {0};

  LL_GPIO_InitTypeDef GPIO_InitStruct = {0};

  LL_RCC_SetI2CClockSource(LL_RCC_I2C1_CLKSOURCE_PCLK1);

  LL_IOP_GRP1_EnableClock(LL_IOP_GRP1_PERIPH_GPIOB);
  /**I2C1 GPIO Configuration
  PB9   ------> I2C1_SDA
  PB8   ------> I2C1_SCL
  */
  GPIO_InitStruct.Pin = LL_GPIO_PIN_9;
  GPIO_InitStruct.Mode = LL_GPIO_MODE_ALTERNATE;
  GPIO_InitStruct.Speed = LL_GPIO_SPEED_FREQ_LOW;
  GPIO_InitStruct.OutputType = LL_GPIO_OUTPUT_OPENDRAIN;
  GPIO_InitStruct.Pull = LL_GPIO_PULL_NO;
  GPIO_InitStruct.Alternate = LL_GPIO_AF_6;
  LL_GPIO_Init(GPIOB, &GPIO_InitStruct);

  GPIO_InitStruct.Pin = LL_GPIO_PIN_8;
  GPIO_InitStruct.Mode = LL_GPIO_MODE_ALTERNATE;
  GPIO_InitStruct.Speed = LL_GPIO_SPEED_FREQ_LOW;
  GPIO_InitStruct.OutputType = LL_GPIO_OUTPUT_OPENDRAIN;
  GPIO_InitStruct.Pull = LL_GPIO_PULL_NO;
  GPIO_InitStruct.Alternate = LL_GPIO_AF_6;
  LL_GPIO_Init(GPIOB, &GPIO_InitStruct);

  /* Peripheral clock enable */
  LL_APB1_GRP1_EnableClock(LL_APB1_GRP1_PERIPH_I2C1);

  /** I2C Initialization
  */
  I2C_InitStruct.PeripheralMode = LL_I2C_MODE_I2C;
  I2C_InitStruct.Timing = 0x10707DBC;
  I2C_InitStruct.AnalogFilter = LL_I2C_ANALOGFILTER_ENABLE;
  I2C_InitStruct.DigitalFilter = 0;
  I2C_InitStruct.OwnAddress1 = 0;
  I2C_InitStruct.TypeAcknowledge = LL_I2C_ACK;
  I2C_InitStruct.OwnAddrSize = LL_I2C_OWNADDRESS1_7BIT;
  LL_I2C_Init(I2C1, &I2C_InitStruct);
  LL_I2C_EnableAutoEndMode(I2C1);
  LL_I2C_SetOwnAddress2(I2C1, 0, LL_I2C_OWNADDRESS2_NOMASK);
  LL_I2C_DisableOwnAddress2(I2C1);
  LL_I2C_DisableGeneralCall(I2C1);
  LL_I2C_EnableClockStretching(I2C1);

}

static void MX_IWDG_Init(void)
{

  LL_IWDG_Enable(IWDG);
  LL_IWDG_EnableWriteAccess(IWDG);
  LL_IWDG_SetPrescaler(IWDG, LL_IWDG_PRESCALER_32);
  LL_IWDG_SetReloadCounter(IWDG, 200);
  while (LL_IWDG_IsReady(IWDG) != 1)
  {
  }

  LL_IWDG_ReloadCounter(IWDG);

}

static void MX_TIM1_Init(void)
{

  LL_TIM_InitTypeDef TIM_InitStruct = {0};
  LL_TIM_OC_InitTypeDef TIM_OC_InitStruct = {0};
  LL_TIM_BDTR_InitTypeDef TIM_BDTRInitStruct = {0};

  LL_GPIO_InitTypeDef GPIO_InitStruct = {0};

  LL_RCC_SetTIMClockSource(LL_RCC_TIM1_CLKSOURCE_PCLK1);

  /* Peripheral clock enable */
  LL_APB2_GRP1_EnableClock(LL_APB2_GRP1_PERIPH_TIM1);

  /* TIM1 interrupt Init */
  NVIC_SetPriority(TIM1_BRK_UP_TRG_COM_IRQn, 0);
  NVIC_EnableIRQ(TIM1_BRK_UP_TRG_COM_IRQn);

  TIM_InitStruct.Prescaler = 0;
  TIM_InitStruct.CounterMode = LL_TIM_COUNTERMODE_UP;
  TIM_InitStruct.Autoreload = PWM_CYCLE;
  TIM_InitStruct.ClockDivision = LL_TIM_CLOCKDIVISION_DIV1;
  TIM_InitStruct.RepetitionCounter = 0;
  LL_TIM_Init(TIM1, &TIM_InitStruct);
  LL_TIM_EnableARRPreload(TIM1);
  LL_TIM_SetClockSource(TIM1, LL_TIM_CLOCKSOURCE_INTERNAL);
  LL_TIM_OC_EnablePreload(TIM1, LL_TIM_CHANNEL_CH1);
  TIM_OC_InitStruct.OCMode = LL_TIM_OCMODE_PWM1;
  TIM_OC_InitStruct.OCState = LL_TIM_OCSTATE_DISABLE;
  TIM_OC_InitStruct.OCNState = LL_TIM_OCSTATE_DISABLE;
  TIM_OC_InitStruct.CompareValue = 0;
  TIM_OC_InitStruct.OCPolarity = LL_TIM_OCPOLARITY_LOW;
  TIM_OC_InitStruct.OCNPolarity = LL_TIM_OCPOLARITY_HIGH;
  TIM_OC_InitStruct.OCIdleState = LL_TIM_OCIDLESTATE_HIGH;
  TIM_OC_InitStruct.OCNIdleState = LL_TIM_OCIDLESTATE_LOW;
  LL_TIM_OC_Init(TIM1, LL_TIM_CHANNEL_CH1, &TIM_OC_InitStruct);
  LL_TIM_OC_DisableFast(TIM1, LL_TIM_CHANNEL_CH1);
  LL_TIM_OC_EnablePreload(TIM1, LL_TIM_CHANNEL_CH2);
  LL_TIM_OC_Init(TIM1, LL_TIM_CHANNEL_CH2, &TIM_OC_InitStruct);
  LL_TIM_OC_DisableFast(TIM1, LL_TIM_CHANNEL_CH2);
  LL_TIM_SetTriggerOutput(TIM1, LL_TIM_TRGO_RESET);
  LL_TIM_SetTriggerOutput2(TIM1, LL_TIM_TRGO2_RESET);
  LL_TIM_DisableMasterSlaveMode(TIM1);
  TIM_BDTRInitStruct.OSSRState = LL_TIM_OSSR_DISABLE;
  TIM_BDTRInitStruct.OSSIState = LL_TIM_OSSI_DISABLE;
  TIM_BDTRInitStruct.LockLevel = LL_TIM_LOCKLEVEL_OFF;
  TIM_BDTRInitStruct.DeadTime = 0;
  TIM_BDTRInitStruct.BreakState = LL_TIM_BREAK_DISABLE;
  TIM_BDTRInitStruct.BreakPolarity = LL_TIM_BREAK_POLARITY_HIGH;
  TIM_BDTRInitStruct.BreakFilter = LL_TIM_BREAK_FILTER_FDIV1;
  TIM_BDTRInitStruct.BreakAFMode = LL_TIM_BREAK_AFMODE_INPUT;
  TIM_BDTRInitStruct.Break2State = LL_TIM_BREAK2_DISABLE;
  TIM_BDTRInitStruct.Break2Polarity = LL_TIM_BREAK2_POLARITY_HIGH;
  TIM_BDTRInitStruct.Break2Filter = LL_TIM_BREAK2_FILTER_FDIV1;
  TIM_BDTRInitStruct.Break2AFMode = LL_TIM_BREAK_AFMODE_INPUT;
  TIM_BDTRInitStruct.AutomaticOutput = LL_TIM_AUTOMATICOUTPUT_DISABLE;
  LL_TIM_BDTR_Init(TIM1, &TIM_BDTRInitStruct);
  LL_IOP_GRP1_EnableClock(LL_IOP_GRP1_PERIPH_GPIOA);
  /**TIM1 GPIO Configuration
  PA8   ------> TIM1_CH1
  PA9   ------> TIM1_CH2
  */
  GPIO_InitStruct.Pin = PWM_A_Pin;
  GPIO_InitStruct.Mode = LL_GPIO_MODE_ALTERNATE;
  GPIO_InitStruct.Speed = LL_GPIO_SPEED_FREQ_LOW;
  GPIO_InitStruct.OutputType = LL_GPIO_OUTPUT_PUSHPULL;
  GPIO_InitStruct.Pull = LL_GPIO_PULL_NO;
  GPIO_InitStruct.Alternate = LL_GPIO_AF_2;
  LL_GPIO_Init(PWM_A_GPIO_Port, &GPIO_InitStruct);

  GPIO_InitStruct.Pin = PWM_B_Pin;
  GPIO_InitStruct.Mode = LL_GPIO_MODE_ALTERNATE;
  GPIO_InitStruct.Speed = LL_GPIO_SPEED_FREQ_LOW;
  GPIO_InitStruct.OutputType = LL_GPIO_OUTPUT_PUSHPULL;
  GPIO_InitStruct.Pull = LL_GPIO_PULL_NO;
  GPIO_InitStruct.Alternate = LL_GPIO_AF_2;
  LL_GPIO_Init(PWM_B_GPIO_Port, &GPIO_InitStruct);

}

static void MX_TIM3_Init(void)
{

  LL_TIM_InitTypeDef TIM_InitStruct = {0};

  LL_GPIO_InitTypeDef GPIO_InitStruct = {0};

  /* Peripheral clock enable */
  LL_APB1_GRP1_EnableClock(LL_APB1_GRP1_PERIPH_TIM3);

  LL_IOP_GRP1_EnableClock(LL_IOP_GRP1_PERIPH_GPIOB);
  /**TIM3 GPIO Configuration
  PB4   ------> TIM3_CH1
  PB5   ------> TIM3_CH2
  */
  GPIO_InitStruct.Pin = ENC_A_Pin;
  GPIO_InitStruct.Mode = LL_GPIO_MODE_ALTERNATE;
  GPIO_InitStruct.Speed = LL_GPIO_SPEED_FREQ_LOW;
  GPIO_InitStruct.OutputType = LL_GPIO_OUTPUT_PUSHPULL;
  GPIO_InitStruct.Pull = LL_GPIO_PULL_NO;
  GPIO_InitStruct.Alternate = LL_GPIO_AF_1;
  LL_GPIO_Init(ENC_A_GPIO_Port, &GPIO_InitStruct);

  GPIO_InitStruct.Pin = ENC_B_Pin;
  GPIO_InitStruct.Mode = LL_GPIO_MODE_ALTERNATE;
  GPIO_InitStruct.Speed = LL_GPIO_SPEED_FREQ_LOW;
  GPIO_InitStruct.OutputType = LL_GPIO_OUTPUT_PUSHPULL;
  GPIO_InitStruct.Pull = LL_GPIO_PULL_NO;
  GPIO_InitStruct.Alternate = LL_GPIO_AF_1;
  LL_GPIO_Init(ENC_B_GPIO_Port, &GPIO_InitStruct);

  TIM_InitStruct.Prescaler = 0;
  TIM_InitStruct.CounterMode = LL_TIM_COUNTERMODE_UP;
  TIM_InitStruct.Autoreload = 65535;
  TIM_InitStruct.ClockDivision = LL_TIM_CLOCKDIVISION_DIV1;
  LL_TIM_Init(TIM3, &TIM_InitStruct);
  LL_TIM_EnableARRPreload(TIM3);
  LL_TIM_SetEncoderMode(TIM3, LL_TIM_ENCODERMODE_X4_TI12);
  LL_TIM_IC_SetActiveInput(TIM3, LL_TIM_CHANNEL_CH1, LL_TIM_ACTIVEINPUT_DIRECTTI);
  LL_TIM_IC_SetPrescaler(TIM3, LL_TIM_CHANNEL_CH1, LL_TIM_ICPSC_DIV1);
  LL_TIM_IC_SetFilter(TIM3, LL_TIM_CHANNEL_CH1, LL_TIM_IC_FILTER_FDIV1);
  LL_TIM_IC_SetPolarity(TIM3, LL_TIM_CHANNEL_CH1, LL_TIM_IC_POLARITY_RISING);
  LL_TIM_IC_SetActiveInput(TIM3, LL_TIM_CHANNEL_CH2, LL_TIM_ACTIVEINPUT_DIRECTTI);
  LL_TIM_IC_SetPrescaler(TIM3, LL_TIM_CHANNEL_CH2, LL_TIM_ICPSC_DIV1);
  LL_TIM_IC_SetFilter(TIM3, LL_TIM_CHANNEL_CH2, LL_TIM_IC_FILTER_FDIV1);
  LL_TIM_IC_SetPolarity(TIM3, LL_TIM_CHANNEL_CH2, LL_TIM_IC_POLARITY_RISING);
  LL_TIM_SetTriggerOutput(TIM3, LL_TIM_TRGO_RESET);
  LL_TIM_DisableMasterSlaveMode(TIM3);

}

static void MX_USART1_UART_Init(void)
{

  LL_USART_InitTypeDef USART_InitStruct = {0};

  LL_GPIO_InitTypeDef GPIO_InitStruct = {0};

  LL_RCC_SetUSARTClockSource(LL_RCC_USART1_CLKSOURCE_PCLK1);

  /* Peripheral clock enable */
  LL_APB2_GRP1_EnableClock(LL_APB2_GRP1_PERIPH_USART1);

  LL_IOP_GRP1_EnableClock(LL_IOP_GRP1_PERIPH_GPIOB);
  /**USART1 GPIO Configuration
  PB6   ------> USART1_TX
  PB7   ------> USART1_RX
  */
  GPIO_InitStruct.Pin = LL_GPIO_PIN_6;
  GPIO_InitStruct.Mode = LL_GPIO_MODE_ALTERNATE;
  GPIO_InitStruct.Speed = LL_GPIO_SPEED_FREQ_LOW;
  GPIO_InitStruct.OutputType = LL_GPIO_OUTPUT_PUSHPULL;
  GPIO_InitStruct.Pull = LL_GPIO_PULL_NO;
  GPIO_InitStruct.Alternate = LL_GPIO_AF_0;
  LL_GPIO_Init(GPIOB, &GPIO_InitStruct);

  GPIO_InitStruct.Pin = LL_GPIO_PIN_7;
  GPIO_InitStruct.Mode = LL_GPIO_MODE_ALTERNATE;
  GPIO_InitStruct.Speed = LL_GPIO_SPEED_FREQ_LOW;
  GPIO_InitStruct.OutputType = LL_GPIO_OUTPUT_PUSHPULL;
  GPIO_InitStruct.Pull = LL_GPIO_PULL_NO;
  GPIO_InitStruct.Alternate = LL_GPIO_AF_0;
  LL_GPIO_Init(GPIOB, &GPIO_InitStruct);

  /* USART1 DMA Init */

  /* USART1_TX Init */
  LL_DMA_SetPeriphRequest(DMA1, LL_DMA_CHANNEL_2, LL_DMAMUX_REQ_USART1_TX);

  LL_DMA_SetDataTransferDirection(DMA1, LL_DMA_CHANNEL_2, LL_DMA_DIRECTION_MEMORY_TO_PERIPH);

  LL_DMA_SetChannelPriorityLevel(DMA1, LL_DMA_CHANNEL_2, LL_DMA_PRIORITY_HIGH);

  LL_DMA_SetMode(DMA1, LL_DMA_CHANNEL_2, LL_DMA_MODE_NORMAL);

  LL_DMA_SetPeriphIncMode(DMA1, LL_DMA_CHANNEL_2, LL_DMA_PERIPH_NOINCREMENT);

  LL_DMA_SetMemoryIncMode(DMA1, LL_DMA_CHANNEL_2, LL_DMA_MEMORY_INCREMENT);

  LL_DMA_SetPeriphSize(DMA1, LL_DMA_CHANNEL_2, LL_DMA_PDATAALIGN_BYTE);

  LL_DMA_SetMemorySize(DMA1, LL_DMA_CHANNEL_2, LL_DMA_MDATAALIGN_BYTE);

  /* USART1 interrupt Init */
  NVIC_SetPriority(USART1_IRQn, 0);
  NVIC_EnableIRQ(USART1_IRQn);

  USART_InitStruct.PrescalerValue = LL_USART_PRESCALER_DIV1;
  USART_InitStruct.BaudRate = COM_BAUD;
  USART_InitStruct.DataWidth = LL_USART_DATAWIDTH_8B;
  USART_InitStruct.StopBits = LL_USART_STOPBITS_1;
  USART_InitStruct.Parity = LL_USART_PARITY_NONE;
  USART_InitStruct.TransferDirection = LL_USART_DIRECTION_TX_RX;
  USART_InitStruct.HardwareFlowControl = LL_USART_HWCONTROL_NONE;
  USART_InitStruct.OverSampling = LL_USART_OVERSAMPLING_8;
  LL_USART_Init(USART1, &USART_InitStruct);
  LL_USART_SetTXFIFOThreshold(USART1, LL_USART_FIFOTHRESHOLD_1_8);
  LL_USART_SetRXFIFOThreshold(USART1, LL_USART_FIFOTHRESHOLD_1_8);
  LL_USART_DisableFIFO(USART1);
  LL_USART_DisableOverrunDetect(USART1);
  LL_USART_ConfigAsyncMode(USART1);

  LL_USART_Enable(USART1);

  /* Polling USART1 initialisation */
  while((!(LL_USART_IsActiveFlag_TEACK(USART1))) || (!(LL_USART_IsActiveFlag_REACK(USART1))))
  {
  }

}

static void MX_DMA_Init(void)
{

  /* Init with LL driver */
  /* DMA controller clock enable */
  LL_AHB1_GRP1_EnableClock(LL_AHB1_GRP1_PERIPH_DMA1);

  /* DMA interrupt init */
  /* DMA1_Channel1_IRQn interrupt configuration */
  NVIC_SetPriority(DMA1_Channel1_IRQn, 1);
  NVIC_EnableIRQ(DMA1_Channel1_IRQn);
  /* DMA1_Channel2_3_IRQn interrupt configuration */
  NVIC_SetPriority(DMA1_Channel2_3_IRQn, 2);
  NVIC_EnableIRQ(DMA1_Channel2_3_IRQn);

}

static void MX_GPIO_Init(void)
{
  LL_GPIO_InitTypeDef GPIO_InitStruct = {0};

  /* GPIO Ports Clock Enable */
  LL_IOP_GRP1_EnableClock(LL_IOP_GRP1_PERIPH_GPIOB);
  LL_IOP_GRP1_EnableClock(LL_IOP_GRP1_PERIPH_GPIOC);
  LL_IOP_GRP1_EnableClock(LL_IOP_GRP1_PERIPH_GPIOF);
  LL_IOP_GRP1_EnableClock(LL_IOP_GRP1_PERIPH_GPIOA);

  /**/
  LL_GPIO_ResetOutputPin(LED2_GPIO_Port, LED2_Pin);

  /**/
  LL_GPIO_ResetOutputPin(LED3_GPIO_Port, LED3_Pin);

  /**/
  LL_GPIO_ResetOutputPin(BEMF_GAIN_GPIO_Port, BEMF_GAIN_Pin);

  /**/
  LL_GPIO_ResetOutputPin(LED0_GPIO_Port, LED0_Pin);

  /**/
  LL_GPIO_ResetOutputPin(LED1_GPIO_Port, LED1_Pin);

  /**/
  GPIO_InitStruct.Pin = LED2_Pin;
  GPIO_InitStruct.Mode = LL_GPIO_MODE_OUTPUT;
  GPIO_InitStruct.Speed = LL_GPIO_SPEED_FREQ_LOW;
  GPIO_InitStruct.OutputType = LL_GPIO_OUTPUT_PUSHPULL;
  GPIO_InitStruct.Pull = LL_GPIO_PULL_NO;
  LL_GPIO_Init(LED2_GPIO_Port, &GPIO_InitStruct);

  /**/
  GPIO_InitStruct.Pin = LED3_Pin;
  GPIO_InitStruct.Mode = LL_GPIO_MODE_OUTPUT;
  GPIO_InitStruct.Speed = LL_GPIO_SPEED_FREQ_LOW;
  GPIO_InitStruct.OutputType = LL_GPIO_OUTPUT_PUSHPULL;
  GPIO_InitStruct.Pull = LL_GPIO_PULL_NO;
  LL_GPIO_Init(LED3_GPIO_Port, &GPIO_InitStruct);

  /**/
  GPIO_InitStruct.Pin = USER_SW_Pin;
  GPIO_InitStruct.Mode = LL_GPIO_MODE_INPUT;
  GPIO_InitStruct.Pull = LL_GPIO_PULL_UP;
  LL_GPIO_Init(USER_SW_GPIO_Port, &GPIO_InitStruct);

  /**/
  GPIO_InitStruct.Pin = GPIO_AUX0_Pin;
  GPIO_InitStruct.Mode = LL_GPIO_MODE_INPUT;
  GPIO_InitStruct.Pull = LL_GPIO_PULL_NO;
  LL_GPIO_Init(GPIO_AUX0_GPIO_Port, &GPIO_InitStruct);

  /**/
  GPIO_InitStruct.Pin = GPIO_AUX1_Pin;
  GPIO_InitStruct.Mode = LL_GPIO_MODE_INPUT;
  GPIO_InitStruct.Pull = LL_GPIO_PULL_NO;
  LL_GPIO_Init(GPIO_AUX1_GPIO_Port, &GPIO_InitStruct);

  /**/
  GPIO_InitStruct.Pin = TP4_Pin;
  GPIO_InitStruct.Mode = LL_GPIO_MODE_INPUT;
  GPIO_InitStruct.Pull = LL_GPIO_PULL_NO;
  LL_GPIO_Init(TP4_GPIO_Port, &GPIO_InitStruct);

  /**/
  GPIO_InitStruct.Pin = BEMF_GAIN_Pin;
  GPIO_InitStruct.Mode = LL_GPIO_MODE_OUTPUT;
  GPIO_InitStruct.Speed = LL_GPIO_SPEED_FREQ_LOW;
  GPIO_InitStruct.OutputType = LL_GPIO_OUTPUT_PUSHPULL;
  GPIO_InitStruct.Pull = LL_GPIO_PULL_NO;
  LL_GPIO_Init(BEMF_GAIN_GPIO_Port, &GPIO_InitStruct);

  /**/
  GPIO_InitStruct.Pin = LED0_Pin;
  GPIO_InitStruct.Mode = LL_GPIO_MODE_OUTPUT;
  GPIO_InitStruct.Speed = LL_GPIO_SPEED_FREQ_LOW;
  GPIO_InitStruct.OutputType = LL_GPIO_OUTPUT_PUSHPULL;
  GPIO_InitStruct.Pull = LL_GPIO_PULL_NO;
  LL_GPIO_Init(LED0_GPIO_Port, &GPIO_InitStruct);

  /**/
  GPIO_InitStruct.Pin = LED1_Pin;
  GPIO_InitStruct.Mode = LL_GPIO_MODE_OUTPUT;
  GPIO_InitStruct.Speed = LL_GPIO_SPEED_FREQ_LOW;
  GPIO_InitStruct.OutputType = LL_GPIO_OUTPUT_PUSHPULL;
  GPIO_InitStruct.Pull = LL_GPIO_PULL_NO;
  LL_GPIO_Init(LED1_GPIO_Port, &GPIO_InitStruct);

  /**/
  GPIO_InitStruct.Pin = TP5_Pin;
  GPIO_InitStruct.Mode = LL_GPIO_MODE_INPUT;
  GPIO_InitStruct.Pull = LL_GPIO_PULL_NO;
  LL_GPIO_Init(TP5_GPIO_Port, &GPIO_InitStruct);

  /**/
  GPIO_InitStruct.Pin = TP6_Pin;
  GPIO_InitStruct.Mode = LL_GPIO_MODE_INPUT;
  GPIO_InitStruct.Pull = LL_GPIO_PULL_NO;
  LL_GPIO_Init(TP6_GPIO_Port, &GPIO_InitStruct);

  /**/
  GPIO_InitStruct.Pin = ENC_Z_Pin;
  GPIO_InitStruct.Mode = LL_GPIO_MODE_INPUT;
  GPIO_InitStruct.Pull = LL_GPIO_PULL_NO;
  LL_GPIO_Init(ENC_Z_GPIO_Port, &GPIO_InitStruct);

}

void Error_Handler(void)
{
  __disable_irq();
  while (1)
  {
  }
}
